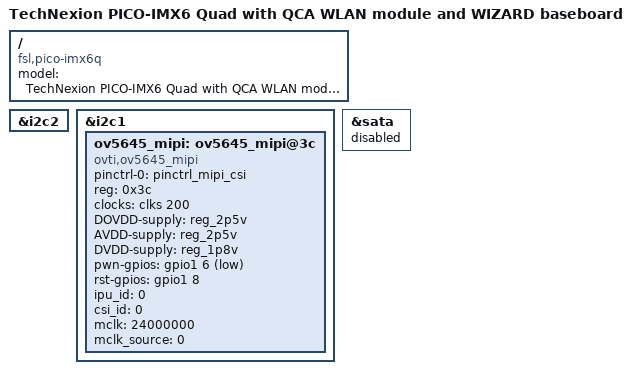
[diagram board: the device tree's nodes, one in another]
/*
 * Copyright 2016,2017,2018 Technexion Ltd.
 *
 * Author: Richard Hu <richard.hu@technexion.com>
 *
 * This program is free software; you can redistribute it and/or modify
 * it under the terms of the GNU General Public License version 2 as
 * published by the Free Software Foundation.
 *
 */
/dts-v1/;

#include "imx6q.dtsi"
#include "imx6qdl-pico-qca.dtsi"
#include "imx6qdl-baseboard_pico_wizard.dtsi"

/ {
	model = "TechNexion PICO-IMX6 Quad with QCA WLAN module and WIZARD baseboard";
	compatible = "fsl,pico-imx6q", "fsl,imx6q";
};

&i2c2 {
	/delete-node/ ov5645_mipi@3c;
};

&i2c1 {
	ov5645_mipi: ov5645_mipi@3c {
		compatible = "ovti,ov5645_mipi";
		pinctrl-names = "default";
		pinctrl-0 = <&pinctrl_mipi_csi>; /* PICO_P69:mipi clock, PICO_P67:power on, PICO_P65:reset */
		reg = <0x3c>;
		clocks = <&clks 200>;
		clock-names = "csi_mclk";
		DOVDD-supply = <&reg_2p5v>;
		AVDD-supply = <&reg_2p5v>;
		DVDD-supply = <&reg_1p8v>;
		pwn-gpios = <&gpio1 6 1>;
		rst-gpios = <&gpio1 8 0>;
		ipu_id = <0>;
		csi_id = <0>;
		mclk = <24000000>;
		mclk_source = <0>;
	};
};

&sata {
	status = "disabled";
};
